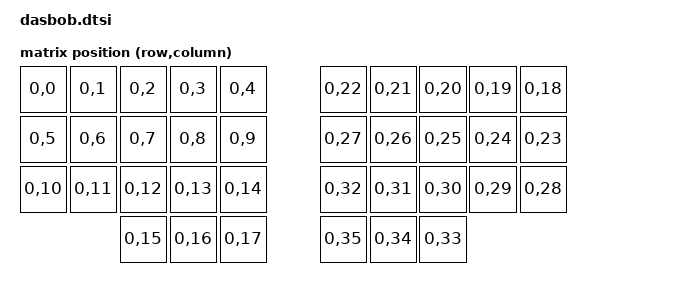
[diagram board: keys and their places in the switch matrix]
/*
 * Copyright (c) 2021 The ZMK Contributors
 *
 * SPDX-License-Identifier: MIT
 */

#include <dt-bindings/zmk/matrix_transform.h>
#include <physical_layouts.dtsi>

/ {

	chosen {
		zmk,physical-layout = &default_layout;
	};

	// Key order matches the keymap positions; units are 1/100 key
	default_layout: default_layout {
		compatible = "zmk,physical-layout";
		display-name = "Default Layout";
		transform = <&default_transform>;
		keys = <
			&key_physical_attrs 100 100    0   0 0 0 0  &key_physical_attrs 100 100  100   0 0 0 0  &key_physical_attrs 100 100  200   0 0 0 0  &key_physical_attrs 100 100  300   0 0 0 0  &key_physical_attrs 100 100  400   0 0 0 0
			&key_physical_attrs 100 100  600   0 0 0 0  &key_physical_attrs 100 100  700   0 0 0 0  &key_physical_attrs 100 100  800   0 0 0 0  &key_physical_attrs 100 100  900   0 0 0 0  &key_physical_attrs 100 100 1000   0 0 0 0
			&key_physical_attrs 100 100    0 100 0 0 0  &key_physical_attrs 100 100  100 100 0 0 0  &key_physical_attrs 100 100  200 100 0 0 0  &key_physical_attrs 100 100  300 100 0 0 0  &key_physical_attrs 100 100  400 100 0 0 0
			&key_physical_attrs 100 100  600 100 0 0 0  &key_physical_attrs 100 100  700 100 0 0 0  &key_physical_attrs 100 100  800 100 0 0 0  &key_physical_attrs 100 100  900 100 0 0 0  &key_physical_attrs 100 100 1000 100 0 0 0
			&key_physical_attrs 100 100    0 200 0 0 0  &key_physical_attrs 100 100  100 200 0 0 0  &key_physical_attrs 100 100  200 200 0 0 0  &key_physical_attrs 100 100  300 200 0 0 0  &key_physical_attrs 100 100  400 200 0 0 0
			&key_physical_attrs 100 100  600 200 0 0 0  &key_physical_attrs 100 100  700 200 0 0 0  &key_physical_attrs 100 100  800 200 0 0 0  &key_physical_attrs 100 100  900 200 0 0 0  &key_physical_attrs 100 100 1000 200 0 0 0
			&key_physical_attrs 100 100  200 300 0 0 0  &key_physical_attrs 100 100  300 300 0 0 0  &key_physical_attrs 100 100  400 300 0 0 0
			&key_physical_attrs 100 100  600 300 0 0 0  &key_physical_attrs 100 100  700 300 0 0 0  &key_physical_attrs 100 100  800 300 0 0 0
		>;
	};

	default_transform: keymap_transform_0 {
		compatible = "zmk,matrix-transform";
		columns = <36>;
		rows = <1>;
		map = <
			RC(0,0)  RC(0,1)  RC(0,2)  RC(0,3)  RC(0,4)    RC(0,22) RC(0,21) RC(0,20) RC(0,19) RC(0,18)
			RC(0,5)  RC(0,6)  RC(0,7)  RC(0,8)  RC(0,9)    RC(0,27) RC(0,26) RC(0,25) RC(0,24) RC(0,23)
			RC(0,10) RC(0,11) RC(0,12) RC(0,13) RC(0,14)   RC(0,32) RC(0,31) RC(0,30) RC(0,29) RC(0,28)
			                  RC(0,15) RC(0,16) RC(0,17)   RC(0,35) RC(0,34) RC(0,33)
		>;
	};

};
